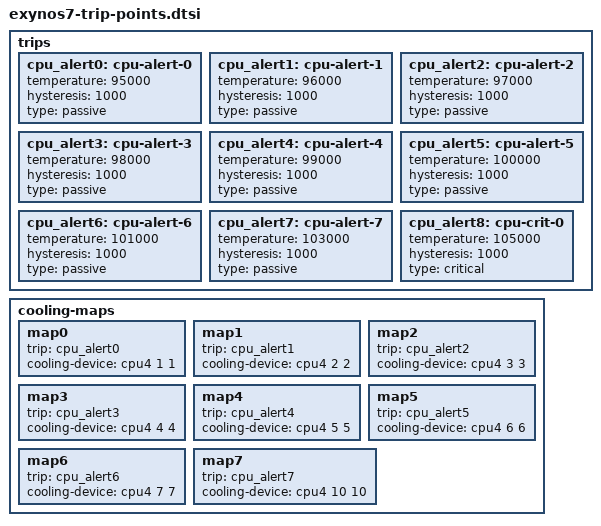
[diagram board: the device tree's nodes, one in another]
/*
 * Device tree sources for default Exynos7 thermal zone definition
 *
 * Copyright (c) 2016 Samsung Electronics Co., Ltd.
 *              http://www.samsung.com
 *
 * This program is free software; you can redistribute it and/or modify
 * it under the terms of the GNU General Public License version 2 as
 * published by the Free Software Foundation.
 *
 */

trips {
cpu_alert0: cpu-alert-0 {
		    temperature = <95000>; /* millicelsius */
		    hysteresis = <1000>; /* millicelsius */
		    type = "passive";
	    };
cpu_alert1: cpu-alert-1 {
		    temperature = <96000>; /* millicelsius */
		    hysteresis = <1000>; /* millicelsius */
		    type = "passive";
	    };
cpu_alert2: cpu-alert-2 {
		    temperature = <97000>; /* millicelsius */
		    hysteresis = <1000>; /* millicelsius */
		    type = "passive";
	    };
cpu_alert3: cpu-alert-3 {
		    temperature = <98000>; /* millicelsius */
		    hysteresis = <1000>; /* millicelsius */
		    type = "passive";
	    };
cpu_alert4: cpu-alert-4 {
		    temperature = <99000>; /* millicelsius */
		    hysteresis = <1000>; /* millicelsius */
		    type = "passive";
	    };
cpu_alert5: cpu-alert-5 {
		    temperature = <100000>; /* millicelsius */
		    hysteresis = <1000>; /* millicelsius */
		    type = "passive";
	    };

cpu_alert6: cpu-alert-6 {
		    temperature = <101000>; /* millicelsius */
		    hysteresis = <1000>; /* millicelsius */
		    type = "passive";
	    };
cpu_alert7: cpu-alert-7 {
		    temperature = <103000>; /* millicelsius */
		    hysteresis = <1000>; /* millicelsius */
		    type = "passive";
	    };
cpu_alert8: cpu-crit-0 {
		    temperature = <105000>; /* millicelsius */
		    hysteresis = <1000>; /* millicelsius */
		    type = "critical";
	    };
};

cooling-maps {
	map0 {
		trip = <&cpu_alert0>;
		cooling-device = <&cpu4 1  1>;
	};

	map1 {
		trip = <&cpu_alert1>;
		cooling-device = <&cpu4 2  2>;
	};
	map2 {
		trip = <&cpu_alert2>;
		cooling-device = <&cpu4 3  3>;
	};
	map3 {
		trip = <&cpu_alert3>;
		cooling-device = <&cpu4 4  4>;
	};

	map4 {
		trip = <&cpu_alert4>;
		cooling-device = <&cpu4 5  5>;
	};

	map5 {
		trip = <&cpu_alert5>;
		cooling-device = <&cpu4 6  6>;
	};

	map6 {
		trip = <&cpu_alert6>;
		cooling-device = <&cpu4 7  7>;
	};

	map7 {
		trip = <&cpu_alert7>;
		cooling-device = <&cpu4 10  10>;
	};
};
